AUTOSAR XML (schema 4-3-0)
package /ComponentTypes
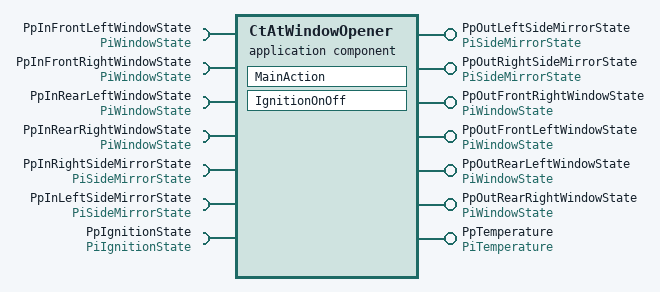
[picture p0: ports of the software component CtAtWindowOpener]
  application sw component type CtAtWindowOpener  # This SWC will have inputs from all buttons. This SWC will have all the date in one SWC which will be used for the ignition activity.
    4 x require port, all with required-interface=PiWindowState:
      PpInFrontLeftWindowState: nonqueued-receiver-com-spec{data-element=DeWindowState, filter=data-filter-type=ALWAYS}
      PpInFrontRightWindowState: nonqueued-receiver-com-spec{data-element=DeWindowState, filter=data-filter-type=ALWAYS, init-value=0}
      PpInRearLeftWindowState: nonqueued-receiver-com-spec{data-element=DeWindowState, filter=data-filter-type=ALWAYS, init-value=0}
      PpInRearRightWindowState: nonqueued-receiver-com-spec{data-element=DeWindowState, filter=data-filter-type=ALWAYS, init-value=0}
    6 x provide port:
      PpOutLeftSideMirrorState: nonqueued-sender-com-spec{data-element=DeSidMirrorState, init-value=0}, provided-interface=PiSideMirrorState
      PpOutRightSideMirrorState: nonqueued-sender-com-spec{data-element=DeSidMirrorState, init-value=0}, provided-interface=PiSideMirrorState
      PpOutFrontRightWindowState: nonqueued-sender-com-spec{data-element=DeWindowState, init-value=0}, provided-interface=PiWindowState
      PpOutFrontLeftWindowState: nonqueued-sender-com-spec{data-element=DeWindowState, init-value=0}, provided-interface=PiWindowState
      PpOutRearLeftWindowState: nonqueued-sender-com-spec{data-element=DeWindowState, init-value=0}, provided-interface=PiWindowState
      PpOutRearRightWindowState: nonqueued-sender-com-spec{data-element=DeWindowState, init-value=0}, provided-interface=PiWindowState
    require port PpInRightSideMirrorState: nonqueued-receiver-com-spec=data-element=DeSidMirrorState, required-interface=PiSideMirrorState
    require port PpInLeftSideMirrorState: nonqueued-receiver-com-spec{data-element=DeSidMirrorState, init-value=0}, required-interface=PiSideMirrorState
    require port PpIgnitionState: nonqueued-receiver-com-spec{data-element=DeIgnitionState, init-value=0}, required-interface=PiIgnitionState
    provide port PpTemperature: nonqueued-sender-com-spec=DeTemp, provided-interface=PiTemperature
    behavior CtAtWindowOpener_InternalBehavior
      7 x data received event:
        DRT_MainAction_PpInFrontLeftWindowState_DeWindowState: start-on-event=MainAction, data=PpInFrontLeftWindowState.DeWindowState
        DRT_MainAction_PpInFrontRightWindowState_DeWindowState: start-on-event=MainAction, data=PpInFrontRightWindowState.DeWindowState
        DRT_MainAction_PpInLeftSideMirrorState_DeSidMirrorState: start-on-event=MainAction, data=PpInLeftSideMirrorState.DeSidMirrorState
        DRT_MainAction_PpInRearLeftWindowState_DeWindowState: start-on-event=MainAction, data=PpInRearLeftWindowState.DeWindowState
        DRT_MainAction_PpInRearRightWindowState_DeWindowState: start-on-event=MainAction, data=PpInRearRightWindowState.DeWindowState
        DRT_MainAction_PpInRightSideMirrorState_DeSidMirrorState: start-on-event=MainAction, data=PpInRightSideMirrorState.DeSidMirrorState
        DRT_IgnitionOn_PpIgnitionState_DeIgnitionState: start-on-event=IgnitionOnOff, data=PpIgnitionState.DeIgnitionState
      runnable MainAction
        data-receive-point-by-arguments:
          6 x access:
            REC_PpInFrontLeftWindowState_DeWindowState: accessed-variable=PpInFrontLeftWindowState.DeWindowState
            REC_PpInFrontRightWindowState_DeWindowState: accessed-variable=PpInFrontRightWindowState.DeWindowState
            REC_PpInLeftSideMirrorState_DeSidMirrorState: accessed-variable=PpInLeftSideMirrorState.DeSidMirrorState
            REC_PpInRearLeftWindowState_DeWindowState: accessed-variable=PpInRearLeftWindowState.DeWindowState
            REC_PpInRearRightWindowState_DeWindowState: accessed-variable=PpInRearRightWindowState.DeWindowState
            REC_PpInRightSideMirrorState_DeSidMirrorState: accessed-variable=PpInRightSideMirrorState.DeSidMirrorState
        data-send-points:
          6 x access:
            SEND_PpOutFrontLeftWindowState_DeWindowState: accessed-variable=PpOutFrontLeftWindowState.DeWindowState
            SEND_PpOutFrontRightWindowState_DeWindowState: accessed-variable=PpOutFrontRightWindowState.DeWindowState
            SEND_PpOutLeftSideMirrorState_DeSidMirrorState: accessed-variable=PpOutLeftSideMirrorState.DeSidMirrorState
            SEND_PpOutRearLeftWindowState_DeWindowState: accessed-variable=PpOutRearLeftWindowState.DeWindowState
            SEND_PpOutRearRightWindowState_DeWindowState: accessed-variable=PpOutRearRightWindowState.DeWindowState
            SEND_PpOutRightSideMirrorState_DeSidMirrorState: accessed-variable=PpOutRightSideMirrorState.DeSidMirrorState
      runnable IgnitionOnOff
        data-receive-point-by-arguments:
          7 x access:
            REC_PpIgnitionState_DeIgnitionState: accessed-variable=PpIgnitionState.DeIgnitionState
            REC_PpInFrontLeftWindowState_DeWindowState: accessed-variable=PpInFrontLeftWindowState.DeWindowState
            REC_PpInFrontRightWindowState_DeWindowState: accessed-variable=PpInFrontRightWindowState.DeWindowState
            REC_PpInLeftSideMirrorState_DeSidMirrorState: accessed-variable=PpInLeftSideMirrorState.DeSidMirrorState
            REC_PpInRearLeftWindowState_DeWindowState: accessed-variable=PpInRearLeftWindowState.DeWindowState
            REC_PpInRearRightWindowState_DeWindowState: accessed-variable=PpInRearRightWindowState.DeWindowState
            REC_PpInRightSideMirrorState_DeSidMirrorState: accessed-variable=PpInRightSideMirrorState.DeSidMirrorState
        data-send-points:
          6 x access:
            SEND_PpOutFrontLeftWindowState_DeWindowState: accessed-variable=PpOutFrontLeftWindowState.DeWindowState
            SEND_PpOutFrontRightWindowState_DeWindowState: accessed-variable=PpOutFrontRightWindowState.DeWindowState
            SEND_PpOutLeftSideMirrorState_DeSidMirrorState: accessed-variable=PpOutLeftSideMirrorState.DeSidMirrorState
            SEND_PpOutRearLeftWindowState_DeWindowState: accessed-variable=PpOutRearLeftWindowState.DeWindowState
            SEND_PpOutRearRightWindowState_DeWindowState: accessed-variable=PpOutRearRightWindowState.DeWindowState
            SEND_PpOutRightSideMirrorState_DeSidMirrorState: accessed-variable=PpOutRightSideMirrorState.DeSidMirrorState
  swc implementation CtAtWindowOpener_Implementation: behavior=CtAtWindowOpener_InternalBehavior
